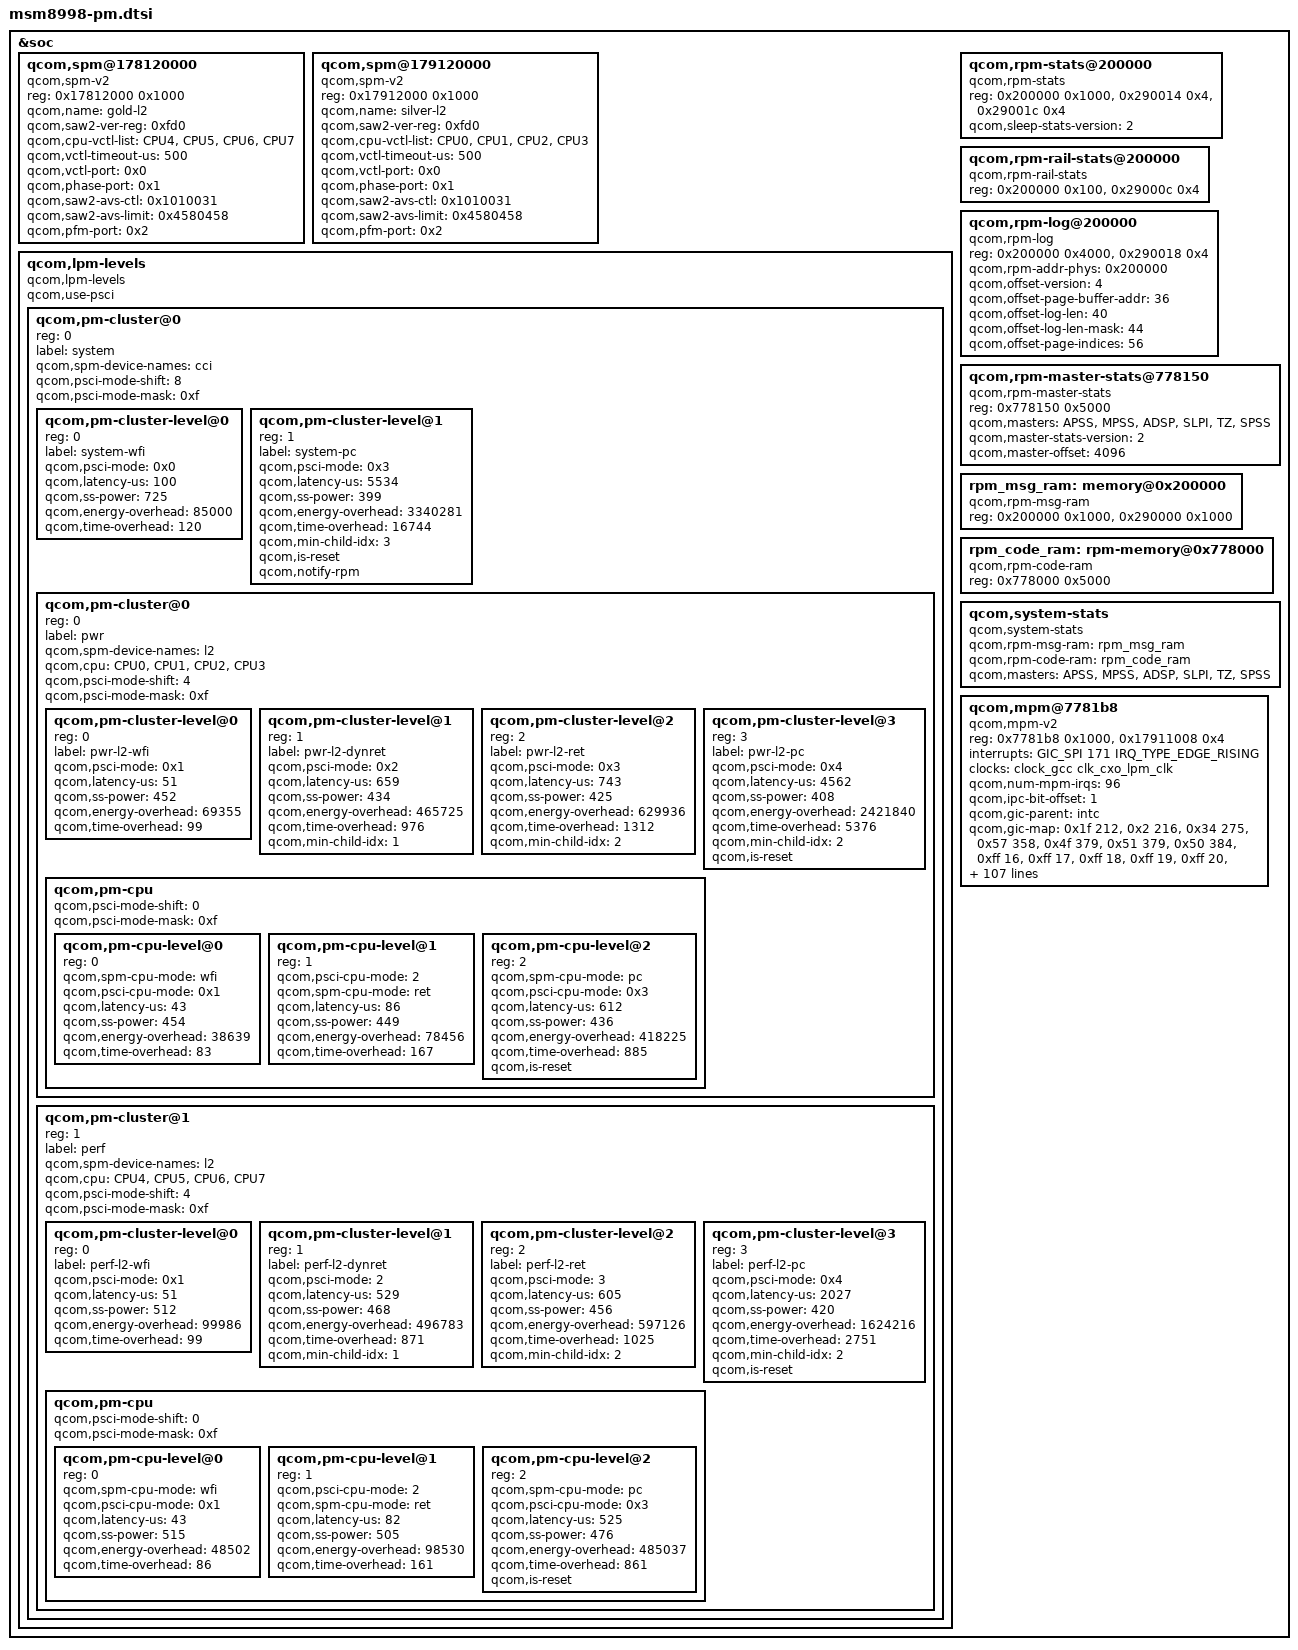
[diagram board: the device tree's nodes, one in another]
/* Copyright (c) 2016-2017, The Linux Foundation. All rights reserved.
 * Copyright (C) 2018 XiaoMi, Inc.
 *
 * This program is free software; you can redistribute it and/or modify
 * it under the terms of the GNU General Public License version 2 and
 * only version 2 as published by the Free Software Foundation.
 *
 * This program is distributed in the hope that it will be useful,
 * but WITHOUT ANY WARRANTY; without even the implied warranty of
 * MERCHANTABILITY or FITNESS FOR A PARTICULAR PURPOSE.  See the
 * GNU General Public License for more details.
 */
#include <dt-bindings/interrupt-controller/arm-gic.h>

&soc {
	qcom,spm@178120000 {
		compatible = "qcom,spm-v2";
		#address-cells = <1>;
		#size-cells = <1>;
		reg = <0x17812000 0x1000>;
		qcom,name = "gold-l2"; /* Gold L2 SAW */
		qcom,saw2-ver-reg = <0xfd0>;
		qcom,cpu-vctl-list = <&CPU4 &CPU5 &CPU6 &CPU7>;
		qcom,vctl-timeout-us = <500>;
		qcom,vctl-port = <0x0>;
		qcom,phase-port = <0x1>;
		qcom,saw2-avs-ctl = <0x1010031>;
		qcom,saw2-avs-limit = <0x4580458>;
		qcom,pfm-port = <0x2>;
	};

	qcom,spm@179120000 {
		compatible = "qcom,spm-v2";
		#address-cells = <1>;
		#size-cells = <1>;
		reg = <0x17912000 0x1000>;
		qcom,name = "silver-l2"; /* Silver L2 SAW */
		qcom,saw2-ver-reg = <0xfd0>;
		qcom,cpu-vctl-list = <&CPU0 &CPU1 &CPU2 &CPU3>;
		qcom,vctl-timeout-us = <500>;
		qcom,vctl-port = <0x0>;
		qcom,phase-port = <0x1>;
		qcom,saw2-avs-ctl = <0x1010031>;
		qcom,saw2-avs-limit = <0x4580458>;
		qcom,pfm-port = <0x2>;
	};

	qcom,lpm-levels {
		compatible = "qcom,lpm-levels";
		qcom,use-psci;
		#address-cells = <1>;
		#size-cells = <0>;
		qcom,pm-cluster@0 {
			reg = <0>;
			#address-cells = <1>;
			#size-cells = <0>;
			label = "system";
			qcom,spm-device-names = "cci";
			qcom,psci-mode-shift = <8>;
			qcom,psci-mode-mask = <0xf>;

			qcom,pm-cluster-level@0{
				reg = <0>;
				label = "system-wfi";
				qcom,psci-mode = <0x0>;
				qcom,latency-us = <100>;
				qcom,ss-power = <725>;
				qcom,energy-overhead = <85000>;
				qcom,time-overhead = <120>;
			};

			qcom,pm-cluster-level@1{ /* E3 */
				reg = <1>;
				label = "system-pc";
				qcom,psci-mode = <0x3>;
				qcom,latency-us = <5534>;
				qcom,ss-power = <399>;
				qcom,energy-overhead = <3340281>;
				qcom,time-overhead = <16744>;
				qcom,min-child-idx = <3>;
				qcom,is-reset;
				qcom,notify-rpm;
			};

			qcom,pm-cluster@0{
				reg = <0>;
				#address-cells = <1>;
				#size-cells = <0>;
				label = "pwr";
				qcom,spm-device-names = "l2";
				qcom,cpu = <&CPU0 &CPU1 &CPU2 &CPU3>;
				qcom,psci-mode-shift = <4>;
				qcom,psci-mode-mask = <0xf>;

				qcom,pm-cluster-level@0{ /* D1 */
					reg = <0>;
					label = "pwr-l2-wfi";
					qcom,psci-mode = <0x1>;
					qcom,latency-us = <51>;
					qcom,ss-power = <452>;
					qcom,energy-overhead = <69355>;
					qcom,time-overhead = <99>;
				};
				qcom,pm-cluster-level@1{ /* D2D */
					reg = <1>;
					label = "pwr-l2-dynret";
					qcom,psci-mode = <0x2>;
					qcom,latency-us = <659>;
					qcom,ss-power = <434>;
					qcom,energy-overhead = <465725>;
					qcom,time-overhead = <976>;
					qcom,min-child-idx = <1>;
				};

				qcom,pm-cluster-level@2{ /* D2E */
					reg = <2>;
					label = "pwr-l2-ret";
					qcom,psci-mode = <0x3>;
					qcom,latency-us = <743>;
					qcom,ss-power = <425>;
					qcom,energy-overhead = <629936>;
					qcom,time-overhead = <1312>;
					qcom,min-child-idx = <2>;
				};

				qcom,pm-cluster-level@3{ /* D4 */
					reg = <3>;
					label = "pwr-l2-pc";
					qcom,psci-mode = <0x4>;
					qcom,latency-us = <4562>;
					qcom,ss-power = <408>;
					qcom,energy-overhead = <2421840>;
					qcom,time-overhead = <5376>;
					qcom,min-child-idx = <2>;
					qcom,is-reset;
				};

				qcom,pm-cpu {
					#address-cells = <1>;
					#size-cells = <0>;
					qcom,psci-mode-shift = <0>;
					qcom,psci-mode-mask = <0xf>;

					qcom,pm-cpu-level@0 { /* C1 */
						reg = <0>;
						qcom,spm-cpu-mode = "wfi";
						qcom,psci-cpu-mode = <0x1>;
						qcom,latency-us = <43>;
						qcom,ss-power = <454>;
						qcom,energy-overhead = <38639>;
						qcom,time-overhead = <83>;
					};

					qcom,pm-cpu-level@1 { /* C2D */
						reg = <1>;
						qcom,psci-cpu-mode = <2>;
						qcom,spm-cpu-mode = "ret";
						qcom,latency-us = <86>;
						qcom,ss-power = <449>;
						qcom,energy-overhead = <78456>;
						qcom,time-overhead = <167>;
					};

					qcom,pm-cpu-level@2 {  /* C3 */
						reg = <2>;
						qcom,spm-cpu-mode = "pc";
						qcom,psci-cpu-mode = <0x3>;
						qcom,latency-us = <612>;
						qcom,ss-power = <436>;
						qcom,energy-overhead = <418225>;
						qcom,time-overhead = <885>;
						qcom,is-reset;
					};
				};
			};

			qcom,pm-cluster@1{
				reg = <1>;
				#address-cells = <1>;
				#size-cells = <0>;
				label = "perf";
				qcom,spm-device-names = "l2";
				qcom,cpu = <&CPU4 &CPU5 &CPU6 &CPU7>;
				qcom,psci-mode-shift = <4>;
				qcom,psci-mode-mask = <0xf>;

				qcom,pm-cluster-level@0{  /* D1 */
					reg = <0>;
					label = "perf-l2-wfi";
					qcom,psci-mode = <0x1>;
					qcom,latency-us = <51>;
					qcom,ss-power = <512>;
					qcom,energy-overhead = <99986>;
					qcom,time-overhead = <99>;
				};

				qcom,pm-cluster-level@1{ /* D2D */
					reg = <1>;
					label = "perf-l2-dynret";
					qcom,psci-mode = <2>;
					qcom,latency-us = <529>;
					qcom,ss-power = <468>;
					qcom,energy-overhead = <496783>;
					qcom,time-overhead = <871>;
					qcom,min-child-idx = <1>;
				};

				qcom,pm-cluster-level@2{ /* D2E */
					reg = <2>;
					label = "perf-l2-ret";
					qcom,psci-mode = <3>;
					qcom,latency-us = <605>;
					qcom,ss-power = <456>;
					qcom,energy-overhead = <597126>;
					qcom,time-overhead = <1025>;
					qcom,min-child-idx = <2>;
				};

				qcom,pm-cluster-level@3{ /* D4 */
					reg = <3>;
					label = "perf-l2-pc";
					qcom,psci-mode = <0x4>;
					qcom,latency-us = <2027>;
					qcom,ss-power = <420>;
					qcom,energy-overhead = <1624216>;
					qcom,time-overhead = <2751>;
					qcom,min-child-idx = <2>;
					qcom,is-reset;
				};

				qcom,pm-cpu {
					#address-cells = <1>;
					#size-cells = <0>;
					qcom,psci-mode-shift = <0>;
					qcom,psci-mode-mask = <0xf>;

					qcom,pm-cpu-level@0 { /* C1 */
						reg = <0>;
						qcom,spm-cpu-mode = "wfi";
						qcom,psci-cpu-mode = <0x1>;
						qcom,latency-us = <43>;
						qcom,ss-power = <515>;
						qcom,energy-overhead = <48502>;
						qcom,time-overhead = <86>;
					};

					qcom,pm-cpu-level@1 { /* C2D */
						reg = <1>;
						qcom,psci-cpu-mode = <2>;
						qcom,spm-cpu-mode = "ret";
						qcom,latency-us = <82>;
						qcom,ss-power = <505>;
						qcom,energy-overhead = <98530>;
						qcom,time-overhead = <161>;
					};

					qcom,pm-cpu-level@2 { /* C3 */
						reg = <2>;
						qcom,spm-cpu-mode = "pc";
						qcom,psci-cpu-mode = <0x3>;
						qcom,latency-us = <525>;
						qcom,ss-power = <476>;
						qcom,energy-overhead = <485037>;
						qcom,time-overhead = <861>;
						qcom,is-reset;
					};
				};
			};
		};
	};

	qcom,rpm-stats@200000 {
		compatible = "qcom,rpm-stats";
		reg = <0x200000 0x1000>,
			<0x290014 0x4>,
			<0x29001c 0x4>;
		reg-names = "phys_addr_base",
			"offset_addr",
			"heap_phys_addrbase";
		qcom,sleep-stats-version = <2>;
	};

	qcom,rpm-rail-stats@200000 {
		compatible = "qcom,rpm-rail-stats";
		reg = <0x200000 0x100>,
			<0x29000c 0x4>;
		reg-names = "phys_addr_base",
			    "offset_addr";
	};

	qcom,rpm-log@200000 {
		compatible = "qcom,rpm-log";
		reg = <0x200000 0x4000>,
			<0x290018 0x4>;
		qcom,rpm-addr-phys = <0x200000>;
		qcom,offset-version = <4>;
		qcom,offset-page-buffer-addr = <36>;
		qcom,offset-log-len = <40>;
		qcom,offset-log-len-mask = <44>;
		qcom,offset-page-indices = <56>;
	};

	qcom,rpm-master-stats@778150 {
		compatible = "qcom,rpm-master-stats";
		reg = <0x778150 0x5000>;
		qcom,masters = "APSS", "MPSS", "ADSP", "SLPI", "TZ", "SPSS";
		qcom,master-stats-version = <2>;
		qcom,master-offset = <4096>;
	};

	rpm_msg_ram: memory@0x200000 {
		compatible = "qcom,rpm-msg-ram";
		reg = <0x200000 0x1000>,
			<0x290000 0x1000>;
	};

	rpm_code_ram: rpm-memory@0x778000 {
		compatible = "qcom,rpm-code-ram";
		reg = <0x778000 0x5000>;
	};

	qcom,system-stats {
		compatible = "qcom,system-stats";
		qcom,rpm-msg-ram = <&rpm_msg_ram>;
		qcom,rpm-code-ram = <&rpm_code_ram>;
		qcom,masters = "APSS", "MPSS", "ADSP", "SLPI", "TZ", "SPSS";
	};

	qcom,mpm@7781b8 {
		compatible = "qcom,mpm-v2";
		reg = <0x7781b8 0x1000>, /* MSM_RPM_MPM_BASE 4K */
		    <0x17911008 0x4>;   /* MSM_APCS_GCC_BASE 4K */
		reg-names = "vmpm", "ipc";
		interrupts = <GIC_SPI 171 IRQ_TYPE_EDGE_RISING>;
		clocks = <&clock_gcc clk_cxo_lpm_clk>;
		clock-names = "xo";
		qcom,num-mpm-irqs = <96>;

		qcom,ipc-bit-offset = <1>;

		qcom,gic-parent = <&intc>;
		qcom,gic-map =
			<0x1f 212>, /* usb30_power_event_irq	*/
			<0x2 216>, /* tsens1_upper_lower_int	*/
			<0x34 275>, /* qmp_usb3_lfps_rxterm_irq_cx	*/
			<0x57 358>, /*  spmi_periph_irq[0]	*/
			<0x4f 379>, /* usb2phy_intr: qusb2phy_dmse_hv	*/
			<0x51 379>, /* usb2phy_intr: qusb2phy_dpse_hv	*/
			<0x50 384>, /* sp_rmb_sp2soc_irq	*/
			<0xff 16>, /* APC0_qgicQTmrHypPhysIrptReq	*/
			<0xff 17>, /* APC3_qgicQTmrSecPhysIrptReq	*/
			<0xff 18>, /* APC0_qgicQTmrNonSecPhysIrptReq	*/
			<0xff 19>, /* APC3_qgicQTmrVirtIrptReq	*/
			<0xff 20>, /* APC0_dbgCommRxFull	*/
			<0xff 21>, /* APC3_dbgCommTxEmpty	*/
			<0xff 22>, /* APC0_qgicPerfMonIrptReq	*/
			<0xff 23>, /* corespm_vote_int[7]	*/
			<0xff 24>, /* APC0_qgicExtFaultIrptReq	*/
			<0xff 28>, /* qgicWakeupSync	*/
			<0xff 29>, /* APCC_cti_SPI_intx	*/
			<0xff 30>, /* APCC_cti_SPI_inty	*/
			<0xff 32>, /* l2spm_vote_int[0]	*/
			<0xff 33>, /* l2spm_vote_int[1]	*/
			<0xff 34>, /* APCC_qgicL2ErrorIrptReq	*/
			<0xff 35>, /* WDT_barkInt	*/
			<0xff 36>, /* WDT_biteExpired	*/
			<0xff 39>, /* QTMR_qgicFrm0VirtIrq	*/
			<0xff 40>, /* QTMR_qgicFrm0PhyIrq	*/
			<0xff 41>, /* QTMR_qgicFrm1PhyIrq	*/
			<0xff 42>, /* QTMR_qgicFrm2PhyIrq	*/
			<0xff 43>, /* QTMR_qgicFrm3PhyIrq	*/
			<0xff 44>, /* QTMR_qgicFrm4PhyIrq	*/
			<0xff 45>, /* QTMR_qgicFrm5PhyIrq	*/
			<0xff 46>, /* QTMR_qgicFrm6PhyIrq	*/
			<0xff 47>, /* rbif_Irq[0]	*/
			<0xff 48>, /* rbif_Irq[1]	*/
			<0xff 52>, /* cci_spm_vote_summary_int	*/
			<0xff 54>, /* ~nERRORIRQ	*/
			<0xff 55>, /* nEVNTCNTOVERFLOW_cci	*/
			<0xff 56>, /* QTMR_qgicFrm0VirtIrq	*/
			<0xff 57>, /* QTMR_qgicFrm0PhyIrq	*/
			<0xff 58>, /* QTMR_qgicFrm1PhyIrq	*/
			<0xff 59>, /* QTMR_qgicFrm2PhyIrq	*/
			<0xff 60>, /* QTMR_qgicFrm3PhyIrq	*/
			<0xff 61>, /* QTMR_qgicFrm4PhyIrq	*/
			<0xff 62>, /* QTMR_qgicFrm5PhyIrq	*/
			<0xff 63>, /* QTMR_qgicFrm6PhyIrq	*/
			<0xff 64>, /* wakeup_counter_irq_OR	*/
			<0xff 65>, /* apc0_vs_alarm	*/
			<0xff 66>, /* apc1_vs_alarm	*/
			<0xff 67>, /* o_pwr_osm_irq	*/
			<0xff 68>, /* o_perf_osm_irq	*/
			<0xff 69>, /* o_pwr_dcvsh_interrupt	*/
			<0xff 70>, /* o_perf_dcvsh_interrupt	*/
			<0xff 73>, /* L2_EXTERRIRQ_C0	*/
			<0xff 74>, /* L2_EXTERRIRQ_C1	*/
			<0xff 75>, /* L2_INTERRIRQ_C0	*/
			<0xff 76>, /* L2_INTERRIRQ_C1	*/
			<0xff 77>, /* L2SPM_svicInt[0]	*/
			<0xff 78>, /* L2SPM_svicInt[1]	*/
			<0xff 79>, /* L2SPM_svicIntSwDone[0]	*/
			<0xff 80>, /* L2SPM_svicIntSwDone[1]	*/
			<0xff 81>, /* l2_avs_err[0]	*/
			<0xff 82>, /* l2_avs_err[1]	*/
			<0xff 83>, /* l2_avs_ack[0]	*/
			<0xff 84>, /* l2_avs_ack[1]	*/
			<0xff 96>, /* uart_dm_intr	*/
			<0xff 97>, /* uart_dm_intr	*/
			<0xff 98>, /* o_qm_interrupt	*/
			<0xff 100>, /* jpeg_vbif_irpt	*/
			<0xff 101>, /* processor_1_user_int	*/
			<0xff 102>, /* processor_1_kernel_int	*/
			<0xff 106>, /* dir_conn_irq_lpa_dsp_2	*/
			<0xff 107>, /* dir_conn_irq_lpa_dsp_1	*/
			<0xff 109>, /* camss_vbif_0_irq	*/
			<0xff 110>, /* csiphy_irq	*/
			<0xff 111>, /* csiphy_irq	*/
			<0xff 112>, /* csiphy_irq	*/
			<0xff 115>, /* mdp_irq	*/
			<0xff 116>, /* vbif_irpt	*/
			<0xff 117>, /* dir_conn_irq_lpa_dsp_0	*/
			<0xff 119>, /* lcc_audio_wrapper_q6	*/
			<0xff 122>, /* PIMEM TPDM BC interrupt	*/
			<0xff 123>, /* PIMEM TPDM TC interrupt	*/
			<0xff 124>, /* dir_conn_irq_sensors_1	*/
			<0xff 125>, /* dir_conn_irq_sensors_0	*/
			<0xff 126>, /* qup_irq	*/
			<0xff 127>, /* qup_irq	*/
			<0xff 128>, /* qup_irq	*/
			<0xff 129>, /* qup_irq	*/
			<0xff 130>, /* qup_irq	*/
			<0xff 131>, /* qup_irq	*/
			<0xff 132>, /* qup_irq	*/
			<0xff 133>, /* qup_irq	*/
			<0xff 134>, /* qup_irq	*/
			<0xff 135>, /* qup_irq	*/
			<0xff 136>, /* qup_irq	*/
			<0xff 137>, /* qup_irq	*/
			<0xff 138>, /* qup_irq	*/
			<0xff 139>, /* uart_dm_intr	*/
			<0xff 140>, /* uart_dm_intr	*/
			<0xff 141>, /* uart_dm_intr	*/
			<0xff 145>, /* uart_dm_intr	*/
			<0xff 146>, /* uart_dm_intr	*/
			<0xff 147>, /* uart_dm_intr	*/
			<0xff 148>, /* osmmu_Cirpt[4]	*/
			<0xff 149>, /* osmmu_Cirpt[5]	*/
			<0xff 151>, /* tsif_irq[0]	*/
			<0xff 152>, /* tsif_irq[1]	*/
			<0xff 153>, /* tspp_irq	*/
			<0xff 154>, /* bam_irq	*/
			<0xff 155>, /* dir_conn_irq_lpa_dsp_5	*/
			<0xff 156>, /* dir_conn_irq_lpa_dsp_4	*/
			<0xff 157>, /* sdcc_irq	*/
			<0xff 158>, /* sdcc_irq	*/
			<0xff 159>, /* lpass_qos_apps_interrupt	*/
			<0xff 160>, /* smmu_PMIrpt	*/
			<0xff 161>, /* sdcc_irq	*/
			<0xff 162>, /* sdcc_irq	*/
			<0xff 163>, /* usb30_ctrl_irq[0]	*/
			<0xff 164>, /* usb30_bam_irq	*/
			<0xff 165>, /* usb30_hs_phy_irq	*/
			<0xff 166>, /* o_lm_int_2qgic	*/
			<0xff 167>, /* pcie20_inta	*/
			<0xff 168>, /* pcie20_intb	*/
			<0xff 169>, /* smmu_Cirpt[12]	*/
			<0xff 170>, /* pcie20_intc	*/
			<0xff 171>, /* pcie20_intd	*/
			<0xff 172>, /* dcvs_int(8)	*/
			<0xff 173>, /* dcvs_int(9)	*/
			<0xff 184>, /* dir_conn_irq_lpa_dsp_3	*/
			<0xff 185>, /* camss_vbif_2_irq	*/
			<0xff 186>, /* mnoc_obs_mainFault	*/
			<0xff 188>, /* q6ss_irq_out(4)	*/
			<0xff 189>, /* q6ss_irq_out(5)	*/
			<0xff 190>, /* q6ss_irq_out(6)	*/
			<0xff 191>, /* q6ss_irq_out(7)	*/
			<0xff 192>, /* audio_out0_irq	*/
			<0xff 194>, /* q6ss_wdog_exp_irq	*/
			<0xff 195>, /* lpass_slimbus_core_ee1_irq	*/
			<0xff 196>, /* lpass_slimbus_bam_ee1_irq	*/
			<0xff 197>, /* resampler_irq[0]	*/
			<0xff 199>, /* qdss_usb_trace_bam_irq	*/
			<0xff 200>, /* rpm_ipc[4]	*/
			<0xff 201>, /* rpm_ipc[5]	*/
			<0xff 202>, /* rpm_ipc[6]	*/
			<0xff 203>, /* rpm_ipc[7]	*/
			<0xff 204>, /* rpm_ipc[20]	*/
			<0xff 205>, /* rpm_ipc[21]	*/
			<0xff 206>, /* rpm_ipc[22]	*/
			<0xff 207>, /* rpm_ipc[23]	*/
			<0xff 208>, /* q6ss_irq_out(4)	*/
			<0xff 209>, /* q6ss_irq_out(5)	*/
			<0xff 210>, /* q6ss_irq_out(6)	*/
			<0xff 211>, /* q6ss_irq_out(7)	*/
			<0xff 213>, /* secure_wdog_bark_irq	*/
			<0xff 214>, /* tsens1_tsens_max_min_int	*/
			<0xff 215>, /* o_bimc_intr[0]	*/
			<0xff 217>, /* ocimem_nonsec_irq	*/
			<0xff 218>, /* sscaon_tmr_timeout_irq	*/
			<0xff 219>, /* q6ss_irq_out(28)	*/
			<0xff 220>, /* spmi_protocol_irq	*/
			<0xff 221>, /* q6ss_irq_out(29)	*/
			<0xff 222>, /* q6ss_irq_out(30)	*/
			<0xff 223>, /* spdm_offline_irq	*/
			<0xff 224>, /* spdm_realtime_irq	*/
			<0xff 225>, /* snoc_obs_mainFault	*/
			<0xff 226>, /* cnoc_obs_mainFault	*/
			<0xff 227>, /* o_ss_xpu3_sec_intr	*/
			<0xff 228>, /* o_tcsr_xpu3_non_sec_summary_intr	*/
			<0xff 229>, /* o_timeout_slave_kpss_summary_intr */
			<0xff 230>, /* o_tcsr_vmidmt_client_sec_summary_intr */
			<0xff 231>, /* o_tcsr_vmidmt_client_non_sec */
			<0xff 232>, /* o_tcsr_vmidmt_cfg_sec_summary_intr */
			<0xff 233>, /* o_tcsr_vmidmt_cfg_non_sec */
			<0xff 234>, /* q6ss_irq_out(31)	*/
			<0xff 235>, /* cpr_irq[0]	*/
			<0xff 236>, /* crypto_core_irq[0]	*/
			<0xff 237>, /* crypto_core_irq[1]	*/
			<0xff 238>, /* crypto_bam_irq[0]	*/
			<0xff 239>, /* crypto_bam_irq[1]	*/
			<0xff 240>, /* summary_irq_hmss	*/
			<0xff 241>, /* dir_conn_irq_hmss_7	*/
			<0xff 242>, /* dir_conn_irq_hmss_6	*/
			<0xff 243>, /* dir_conn_irq_hmss_5	*/
			<0xff 244>, /* dir_conn_irq_hmss_4	*/
			<0xff 245>, /* dir_conn_irq_hmss_3	*/
			<0xff 246>, /* dir_conn_irq_hmss_2	*/
			<0xff 247>, /* dir_conn_irq_hmss_1	*/
			<0xff 248>, /* dir_conn_irq_hmss_0	*/
			<0xff 249>, /* summary_irq_hmss_tz	*/
			<0xff 250>, /* cpr_irq[3]	*/
			<0xff 251>, /* cpr_irq[2]	*/
			<0xff 252>, /* cpr_irq[1]	*/
			<0xff 253>, /* sdcc_pwr_cmd_irq	*/
			<0xff 254>, /* sdio_wakeup_irq	*/
			<0xff 255>, /* cpr_irq[0]	*/
			<0xff 256>, /* smmu_Cirpt[13]	*/
			<0xff 257>, /* smmu_Cirpt[14]	*/
			<0xff 258>, /* smmu_Cirpt[0]	*/
			<0xff 259>, /* sdcc_pwr_cmd_irq	*/
			<0xff 260>, /* sdio_wakeup_irq	*/
			<0xff 261>, /* o_tcsr_mmu_nsgcfglrpt_summary_intr */
			<0xff 262>, /* o_tcsr_mmu_gcfglrpt_summary_intr	*/
			<0xff 263>, /* o_tcsr_mmu_nsglrpt_summary_intr	*/
			<0xff 264>, /* o_tcsr_mmu_glrpt_summary_intr	*/
			<0xff 265>, /* vbif_irpt	*/
			<0xff 266>, /* smmu_PMIrpt	*/
			<0xff 267>, /* smmu_Cirpt[3]	*/
			<0xff 268>, /* q6ss_irq_out(31)	*/
			<0xff 269>, /* rpm_wdog_expired_irq	*/
			<0xff 270>, /* bam_irq	*/
			<0xff 271>, /* bam_irq	*/
			<0xff 272>, /* q6ss_irq_out(28)	*/
			<0xff 273>, /* q6ss_irq_out(29)	*/
			<0xff 274>, /* q6ss_irq_out(30)	*/
			<0xff 276>, /* osmmu_Cirpt [4]	*/
			<0xff 277>, /* osmmu_Cirpt [5]	*/
			<0xff 278>, /* usb30_ctrl_irq[1]	*/
			<0xff 279>, /* osmmu_Cirpt [6]	*/
			<0xff 280>, /* osmmu_Cirpt [7]	*/
			<0xff 281>, /* osmmu_Cirpt [8]	*/
			<0xff 282>, /* osmmu_Cirpt [9]	*/
			<0xff 283>, /* osmmu_Cirpt [10]	*/
			<0xff 284>, /* osmmu_Cirpt [11]	*/
			<0xff 285>, /* osmmu_Cirpt [12]	*/
			<0xff 286>, /* osmmu_Cirpt [13]	*/
			<0xff 287>, /* osmmu_Cirpt [14]	*/
			<0xff 288>, /* osmmu_Cirpt [15]	*/
			<0xff 289>, /* ufs_ice_sec_level_irq	*/
			<0xff 290>, /* cpr_irq[4]	*/
			<0xff 291>, /* smmu_Cirpt[2]	*/
			<0xff 292>, /* osmmu_Cirpt [16]	*/
			<0xff 293>, /* osmmu_Cirpt [17]	*/
			<0xff 294>, /* osmmu_Cirpt [18]	*/
			<0xff 295>, /* osmmu_Cirpt [0]	*/
			<0xff 296>, /* osmmu_PMIrpt	*/
			<0xff 297>, /* ufs_intrq	*/
			<0xff 298>, /* osmmu_Cirpt [1]	*/
			<0xff 299>, /* osmmu_Cirpt [2]	*/
			<0xff 300>, /* osmmu_Cirpt [3]	*/
			<0xff 301>, /* smmu_Cirpt[1]	*/
			<0xff 302>, /* qdss_etrbytecnt_irq	*/
			<0xff 303>, /* smmu_Cirpt[0]	*/
			<0xff 304>, /* osmmu_Cirpt [19]	*/
			<0xff 305>, /* osmmu_Cirpt [20]	*/
			<0xff 306>, /* osmmu_Cirpt [21]	*/
			<0xff 307>, /* osmmu_Cirpt [22]	*/
			<0xff 308>, /* osmmu_Cirpt [23]	*/
			<0xff 310>, /* pcie20_global_int	*/
			<0xff 311>, /* pcie20_int_edma_int	*/
			<0xff 316>, /* lpass_hdmitx_interrupt_ext	*/
			<0xff 317>, /* rbif_irq	*/
			<0xff 318>, /* gpu_cc_gpu_cx_gds_hw_ctrl_irq_out */
			<0xff 319>, /* VENUS_IRQ	*/
			<0xff 323>, /* lpass_slimbus1_core_ee1_irq	*/
			<0xff 324>, /* lpass_slimbus1_bam_ee1_irq	*/
			<0xff 325>, /* camss_irq18	*/
			<0xff 326>, /* camss_irq0	*/
			<0xff 327>, /* camss_irq1	*/
			<0xff 328>, /* camss_irq2	*/
			<0xff 329>, /* camss_irq3	*/
			<0xff 330>, /* camss_irq4	*/
			<0xff 331>, /* camss_irq5	*/
			<0xff 332>, /* GC_SYS_irq_0	*/
			<0xff 333>, /* GC_SYS_irq_1	*/
			<0xff 334>, /* GC_SYS_irq_2	*/
			<0xff 335>, /* GC_SYS_irq_3	*/
			<0xff 336>, /* camss_irq13	*/
			<0xff 337>, /* camss_irq14	*/
			<0xff 338>, /* camss_irq15	*/
			<0xff 339>, /* camss_irq16	*/
			<0xff 340>, /* camss_irq17	*/
			<0xff 341>, /* camss_irq6	*/
			<0xff 342>, /* smmu_Cirpt[15]	*/
			<0xff 343>, /* bam_irq[0]	*/
			<0xff 344>, /* uart_dm_intr	*/
			<0xff 345>, /* camss_irq7	*/
			<0xff 346>, /* camss_irq8	*/
			<0xff 347>, /* camss_irq9	*/
			<0xff 348>, /* camss_irq10	*/
			<0xff 350>, /* camss_irq12	*/
			<0xff 351>, /* sif_aud_dec_out_irq_ext	*/
			<0xff 356>, /* vbif_nrt_irpt	*/
			<0xff 357>, /* Nonfatal pIMEM interrupt	*/
			<0xff 359>, /* spmi_periph_irq[1]	*/
			<0xff 360>, /* fatal pIMEM interrupt	*/
			<0xff 361>, /* osmmu_Cirpt[0]	*/
			<0xff 362>, /* osmmu_Cirpt[1]	*/
			<0xff 363>, /* osmmu_Cirpt[2]	*/
			<0xff 364>, /* osmmu_Cirpt[3]	*/
			<0xff 365>, /* ipa_irq(0)	*/
			<0xff 366>, /* osmmu_PMIrpt	*/
			<0xff 380>, /* sp_sp2apps_irq[0]	*/
			<0xff 381>, /* sp_sp2apps_irq[1]	*/
			<0xff 382>, /* sp_sp2apps_irq[2]	*/
			<0xff 383>, /* sp_sp2apps_irq[3]	*/
			<0xff 385>, /* osmmu_CIrpt[12]	*/
			<0xff 386>, /* osmmu_CIrpt[13]	*/
			<0xff 387>, /* osmmu_CIrpt[14]	*/
			<0xff 388>, /* osmmu_CIrpt[15]	*/
			<0xff 389>, /* osmmu_CIrpt[16]	*/
			<0xff 390>, /* osmmu_CIrpt[17]	*/
			<0xff 391>, /* osmmu_CIrpt[18]	*/
			<0xff 392>, /* osmmu_CIrpt[19]	*/
			<0xff 393>, /* o_dcc_crc_fail_int	*/
			<0xff 395>, /* aggre1_obs_mainfault	*/
			<0xff 396>, /* aggr1_smmu_cirpt[0]	*/
			<0xff 397>, /* aggr1_smmu_cirpt[1]	*/
			<0xff 398>, /* aggr1_smmu_cirpt[2]	*/
			<0xff 399>, /* aggr1_smmu_cirpt[3]	*/
			<0xff 400>, /* aggr1_smmu_cirpt[4]	*/
			<0xff 401>, /* aggr1_smmu_cirpt[5]	*/
			<0xff 402>, /* aggr1_smmu_cirpt[6]	*/
			<0xff 403>, /* aggr1_smmu_pmirpt	*/
			<0xff 404>, /* aggre2noc_obs_mainFault	*/
			<0xff 405>, /* osmmu_CIrpt[0]	*/
			<0xff 406>, /* osmmu_CIrpt[1]	*/
			<0xff 407>, /* osmmu_CIrpt[2]	*/
			<0xff 408>, /* osmmu_CIrpt[3]	*/
			<0xff 409>, /* osmmu_CIrpt[4]	*/
			<0xff 410>, /* osmmu_CIrpt[5]	*/
			<0xff 411>, /* o_dcc_task_done_int	*/
			<0xff 412>, /* vsense_alarm_irq	*/
			<0xff 413>, /* osmmu_PMIrpt	*/
			<0xff 414>, /* pmic_arb_trans_done_irq[0]	*/
			<0xff 415>, /* pmic_arb_trans_done_irq[1]	*/
			<0xff 416>, /* rpm_ipc[28]	*/
			<0xff 417>, /* rpm_ipc[29]	*/
			<0xff 418>, /* rpm_ipc[30]	*/
			<0xff 419>, /* rpm_ipc[31]	*/
			<0xff 420>, /* qup_irq	*/
			<0xff 421>, /* qup_irq	*/
			<0xff 422>, /* wd_bite_apps	*/
			<0xff 423>, /* lpass_qos_apps_interrupt	*/
			<0xff 424>, /* ipa_irq(2)	*/
			<0xff 425>, /* smmu_Cirpt[1]	*/
			<0xff 426>, /* smmu_Cirpt[2]	*/
			<0xff 427>, /* smmu_Cirpt[3]	*/
			<0xff 428>, /* smmu_Cirpt[4]	*/
			<0xff 429>, /* smmu_Cirpt[5]	*/
			<0xff 430>, /* smmu_Cirpt[6]	*/
			<0xff 431>, /* smmu_Cirpt[7]	*/
			<0xff 432>, /* smmu_Cirpt[8]	*/
			<0xff 433>, /* smmu_Cirpt[9]	*/
			<0xff 434>, /* smmu_Cirpt[10]	*/
			<0xff 435>, /* smmu_Cirpt[11]	*/
			<0xff 436>, /* smmu_Cirpt[16]	*/
			<0xff 437>, /* pcie20_0_int_msi_dev0	*/
			<0xff 438>, /* pcie20_0_int_msi_dev1	*/
			<0xff 439>, /* pcie20_0_int_msi_dev2	*/
			<0xff 440>, /* pcie20_0_int_msi_dev3	*/
			<0xff 441>, /* pcie20_0_int_msi_dev4	*/
			<0xff 442>, /* pcie20_0_int_msi_dev5	*/
			<0xff 443>, /* pcie20_0_int_msi_dev6	*/
			<0xff 444>, /* pcie20_0_int_msi_dev7	*/
			<0xff 445>, /* o_wcss_apps_intr[0]	*/
			<0xff 446>, /* o_wcss_apps_intr[1]	*/
			<0xff 447>, /* o_wcss_apps_intr[2]	*/
			<0xff 448>, /* o_wcss_apps_intr[3]	*/
			<0xff 449>, /* o_wcss_apps_intr[4]	*/
			<0xff 450>, /* o_wcss_apps_intr[5]	*/
			<0xff 452>, /* o_wcss_apps_intr[6]	*/
			<0xff 453>, /* o_wcss_apps_intr[7]	*/
			<0xff 454>, /* o_wcss_apps_intr[8]	*/
			<0xff 455>, /* o_wcss_apps_intr[9]	*/
			<0xff 456>, /* o_wcss_apps_intr[10]	*/
			<0xff 457>, /* o_wcss_apps_intr[11]	*/
			<0xff 458>, /* o_wcss_apps_intr[12]	*/
			<0xff 461>, /* o_ocimem_nonsec_irq	*/
			<0xff 462>, /* tsens1_tsens_critical_int	*/
			<0xff 463>, /* aggr1_smmu_cirpt[7]	*/
			<0xff 464>, /* ipa_bam_irq(0)	*/
			<0xff 465>, /* ipa_bam_irq(2)	*/
			<0xff 466>, /* ssc_uart_int	*/
			<0xff 468>, /* cri_cm_irq_tz	*/
			<0xff 469>, /* cri_cm_irq_hyp	*/
			<0xff 471>, /* mmss_bimc_smmu_gds_hw_ctrl_irq_out */
			<0xff 472>, /* gcc_gds_hw_ctrl_irq_out	*/
			<0xff 473>, /* lcc_audio_core_smmu_gds_hw_ctrl */
			<0xff 477>, /* tsens0_tsens_critical_int	*/
			<0xff 478>, /* tsens0_tsens_max_min_int	*/
			<0xff 480>, /* q6ss_wdog_expired_irq	*/
			<0xff 481>, /* mss_ipc_out_irq[4]	*/
			<0xff 482>, /* mss_ipc_out_irq[5]	*/
			<0xff 483>, /* mss_ipc_out_irq[6]	*/
			<0xff 484>, /* mss_ipc_out_irq[7]	*/
			<0xff 485>, /* mss_ipc_out_irq[28]	*/
			<0xff 486>, /* mss_ipc_out_irq[29]	*/
			<0xff 487>, /* mss_ipc_out_irq[30]	*/
			<0xff 488>, /* mss_ipc_out_irq[31]	*/
			<0xff 489>, /* skl_core_irq	*/
			<0xff 490>, /* tsens0_upper_lower_int	*/
			<0xff 494>, /* osmmu_CIrpt[6]	*/
			<0xff 495>, /* osmmu_CIrpt[7]	*/
			<0xff 496>, /* osmmu_CIrpt[8]	*/
			<0xff 497>, /* osmmu_CIrpt[9]	*/
			<0xff 498>, /* osmmu_CIrpt[10]	*/
			<0xff 499>, /* osmmu_CIrpt[11]	*/
			<0xff 503>; /* o_bimc_intr[1]	*/

		qcom,gpio-parent = <&tlmm>;
		qcom,gpio-map = <3  1>,
			<4  5>,
			<5  9>,
			<6  11>,
			<7  66>,
			<8  22>,
			<9  24>,
			<10  26>,
			<11  34>,
			<12  36>,
			<13  37>, /* PCIe0 */
			<14  38>,
			<15  40>,
			<16  42>,
			<17  46>,
			<18  50>,
			<0xff 52>,
			<19  53>,
			<20  54>,
			<21  56>,
			<22  57>,
			<23  58>,
			<24  59>,
			<25  60>,
			<26  61>,
			<27  62>,
			<28  63>,
			<29  64>,
			<30  71>,
			<31  73>,
			<32  77>,
			<33  78>,
			<34  79>,
			<35  80>,
			<36  82>,
			<37  86>,
			<38  91>,
			<39  92>,
			<40  95>,
			<41  97>,
			<42  101>,
			<43  104>,
			<44  106>,
			<45  108>,
			<46  112>,
			<47  113>,
			<48  110>,
			<50  127>,
			<51  115>,
			<54  116>, /* PCIe2 */
			<55  117>,
			<56  118>,
			<57  119>,
			<58  120>,
			<59  121>,
			<60  122>,
			<61  123>,
			<62  124>,
			<63  125>,
			<64  126>,
			<65  129>,
			<66  131>,
			<67  132>, /* PCIe1 */
			<68  133>,
			<69  145>;
	};
};
